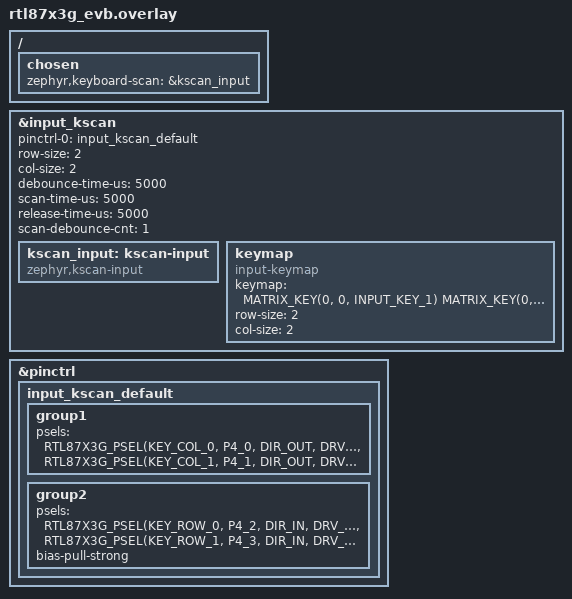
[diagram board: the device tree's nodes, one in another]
/*
 * Copyright(c) 2025, Realtek Semiconductor Corporation.
 *
 * SPDX-License-Identifier: Apache-2.0
 */

#include <zephyr/dt-bindings/input/input-event-codes.h>
#include <zephyr/dt-bindings/input/keymap.h>

/ {
	chosen {
		zephyr,keyboard-scan = &kscan_input;
	};
};

&input_kscan {
	pinctrl-0 = <&input_kscan_default>;
	pinctrl-names = "default";
	row-size = <2>;
	col-size = <2>;
	debounce-time-us = <5000>;
	scan-time-us = <5000>;
	release-time-us = <5000>;
	scan-debounce-cnt = <1>;
	status = "okay";
	kscan_input: kscan-input {
		compatible = "zephyr,kscan-input";
	};
	keymap {
		compatible = "input-keymap";
		keymap = <
			MATRIX_KEY(0, 0, INPUT_KEY_1)
			MATRIX_KEY(0, 1, INPUT_KEY_2)
			MATRIX_KEY(1, 0, INPUT_KEY_3)
			MATRIX_KEY(1, 1, INPUT_KEY_4)
		>;
		row-size = <2>;
		col-size = <2>;
	};
};

&pinctrl {
	input_kscan_default: input_kscan_default {
		group1 {
			psels = <RTL87X3G_PSEL(KEY_COL_0, P4_0, DIR_OUT, DRV_LOW, PULL_NONE)>,
			<RTL87X3G_PSEL(KEY_COL_1, P4_1, DIR_OUT, DRV_LOW, PULL_NONE)>;
		};
		group2 {
			psels = <RTL87X3G_PSEL(KEY_ROW_0, P4_2, DIR_IN, DRV_LOW, PULL_UP)>,
			<RTL87X3G_PSEL(KEY_ROW_1, P4_3, DIR_IN, DRV_LOW, PULL_UP)>;
			bias-pull-strong;
		};
	};
};
